AUTOSAR XML (schema 4-2-2)
package /EB/SoftwareComponents
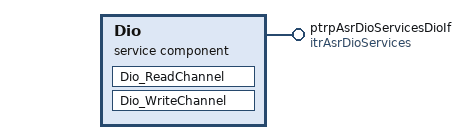
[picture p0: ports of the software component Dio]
  service sw component type Dio: category=ASR_Interfaces
    provide port ptrpAsrDioServicesDioIf: provided-interface=itrAsrDioServices
    behavior Dio_IB: handle-termination-and-restart=NO-SUPPORT
      runnable Dio_ReadChannel: external-triggering-point=ptrpAsrDioServicesDioIf.Dio_ReadChannel
      runnable Dio_WriteChannel: external-triggering-point=ptrpAsrDioServicesDioIf.Dio_WriteChannel, symbol=Dio_DummyRunnable
package /EB/TriggerInterfaces
  trigger interface itrAsrDioServices
    trigger Dio_ReadChannel: trigger-period={cse-code=1000, cse-code-factor=0}
    trigger Dio_WriteChannel: trigger-period={cse-code=1000, cse-code-factor=0}
